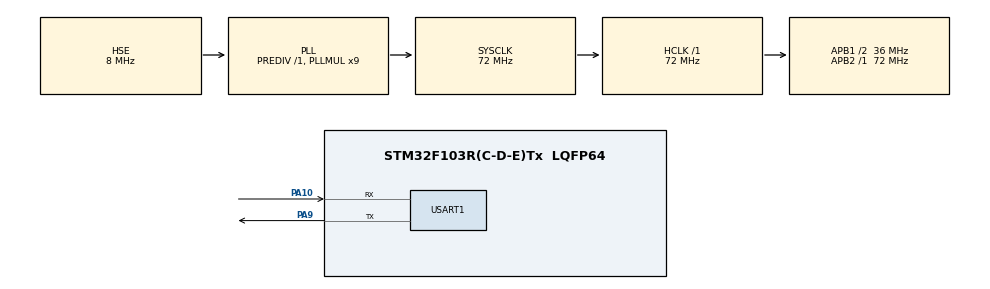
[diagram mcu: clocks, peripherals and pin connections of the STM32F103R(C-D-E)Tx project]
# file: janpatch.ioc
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Mcu.Family=STM32F1
Mcu.Name=STM32F103R(C-D-E)Tx
Mcu.Package=LQFP64
NVIC.PriorityGroup=NVIC_PRIORITYGROUP_4
PA10.Mode=Asynchronous
PA10.Signal=USART1_RX
PA13.Mode=Serial_Wire
PA13.Signal=SYS_JTMS-SWDIO
PA14.Mode=Serial_Wire
PA14.Signal=SYS_JTCK-SWCLK
PA9.Mode=Asynchronous
PA9.Signal=USART1_TX
PC14-OSC32_IN.Mode=LSE-External-Oscillator
PC14-OSC32_IN.Signal=RCC_OSC32_IN
PC15-OSC32_OUT.Mode=LSE-External-Oscillator
PC15-OSC32_OUT.Signal=RCC_OSC32_OUT
PD0-OSC_IN.Mode=HSE-External-Oscillator
PD0-OSC_IN.Signal=RCC_OSC_IN
PD1-OSC_OUT.Mode=HSE-External-Oscillator
PD1-OSC_OUT.Signal=RCC_OSC_OUT
ProjectManager.HeapSize=0x200
ProjectManager.StackSize=0x400
ProjectManager.TargetToolchain=MDK-ARM V5.32
RCC.AHBFreq_Value=72000000
RCC.APB1CLKDivider=RCC_HCLK_DIV2
RCC.APB1Freq_Value=36000000
RCC.APB1TimFreq_Value=72000000
RCC.APB2Freq_Value=72000000
RCC.APB2TimFreq_Value=72000000
RCC.HCLKFreq_Value=72000000
RCC.PLLMUL=RCC_PLL_MUL9
RCC.PLLSourceVirtual=RCC_PLLSOURCE_HSE
RCC.SYSCLKFreq_VALUE=72000000
RCC.SYSCLKSource=RCC_SYSCLKSOURCE_PLLCLK
RCC.USBFreq_Value=72000000
USART1.VirtualMode=VM_ASYNC
board=custom

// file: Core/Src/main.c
/* USER CODE BEGIN Header */
/**
  ******************************************************************************
  * @file           : main.c
  * @brief          : Main program body
  ******************************************************************************
  * @attention
  *
  * Copyright (c) 2024 STMicroelectronics.
  * All rights reserved.
  *
  * This software is licensed under terms that can be found in the LICENSE file
  * in the root directory of this software component.
  * If no LICENSE file comes with this software, it is provided AS-IS.
  *
  ******************************************************************************
  */
/* USER CODE END Header */
#include "main.h"
#include "usart.h"
#include "gpio.h"

/* USER CODE BEGIN Includes */
#include "stdio.h"
#define FOTA_TARGET_ADDRESS 0x08010000
uint32_t Flash_Read(uint32_t address, uint8_t *data, uint32_t length)
{
    while(length--)
    {
        *(data++)=*((uint8_t*)address++);
    }
		return 0;
}

uint32_t Flash_Erase(uint32_t address)
{
    FLASH_EraseInitTypeDef FlashSet;
    FlashSet.TypeErase = FLASH_TYPEERASE_PAGES;
    FlashSet.PageAddress = address;
    FlashSet.NbPages = 1;
    /*设置PageError，调用擦除函数*/
    uint32_t PageError = 0;
    HAL_FLASH_Unlock();
    HAL_FLASHEx_Erase(&FlashSet, &PageError);
    HAL_FLASH_Lock();
		return 0;
}

uint32_t Flash_Write(uint32_t address, uint8_t *data, uint32_t length)
{
    uint8_t buff[4] = {0xFF, 0xFF, 0xFF, 0xFF};
    uint32_t len = length / 4;
    // 解锁Flash
    HAL_FLASH_Unlock();

    // 写入数据到指定地址
    while(len--)
    {
      HAL_FLASH_Program(FLASH_TYPEPROGRAM_WORD, address, *((uint32_t *)data));
      address += 4;
      data += 4;
    }

    len = length % 4;

    for(int i = 0; i < len; i++)
      buff[i] = data[i];

    HAL_FLASH_Program(FLASH_TYPEPROGRAM_WORD, address, *((uint32_t *)buff));

    // 重新锁定Flash
    HAL_FLASH_Lock();
		return 0;
}

/* USER CODE END Includes */

/* USER CODE BEGIN PTD */
#include "janpatch.h"

static janpatch_file_t source = {
  .file_address = FOTA_TARGET_ADDRESS,
  // .file_size = 47352,
};

static janpatch_file_t patch = {
  .file_address = 0x08030000,
  // .file_size = 8580,
};

static janpatch_file_t target = {
  .file_address = FOTA_TARGET_ADDRESS,
  .file_size = 64 * 1024,
};

static struct janpatch_mcu_config janpatch_mcu_config = {
  .flash_erase = Flash_Erase,
  .flash_read = Flash_Read,
  .flash_write = Flash_Write,
};

/* USER CODE END PTD */

void SystemClock_Config(void);

int main(void)
{

  /* MCU Configuration--------------------------------------------------------*/

  /* Reset of all peripherals, Initializes the Flash interface and the Systick. */
  HAL_Init();

  /* Configure the system clock */
  SystemClock_Config();

  /* Initialize all configured peripherals */
  MX_GPIO_Init();
  MX_USART1_UART_Init();
  /* USER CODE BEGIN 2 */
  uint8_t ret = 0;
  ret = janpatch_mcu_cinfig_fota(&janpatch_mcu_config, &source, &patch, &target);
  // if(ret == 0){
  //   uint8_t val = 0;
  //   for(int i = 0; i < target.file_seek; i++) {
  //     Flash_Read(FOTA_TARGET_ADDRESS + i, &val, 1);
  //       if(i % 2048 == 0) printf("\r\n");
  //     if(i % 16 == 0) printf("\r\n%08X: ", i);
  //     printf("%02X ", val);
  //   }
  // }
  /* Infinite loop */
  while (1)
  {

  }
}

void SystemClock_Config(void)
{
  RCC_OscInitTypeDef RCC_OscInitStruct = {0};
  RCC_ClkInitTypeDef RCC_ClkInitStruct = {0};

  /** Initializes the RCC Oscillators according to the specified parameters
  * in the RCC_OscInitTypeDef structure.
  */
  RCC_OscInitStruct.OscillatorType = RCC_OSCILLATORTYPE_HSE;
  RCC_OscInitStruct.HSEState = RCC_HSE_ON;
  RCC_OscInitStruct.HSEPredivValue = RCC_HSE_PREDIV_DIV1;
  RCC_OscInitStruct.HSIState = RCC_HSI_ON;
  RCC_OscInitStruct.PLL.PLLState = RCC_PLL_ON;
  RCC_OscInitStruct.PLL.PLLSource = RCC_PLLSOURCE_HSE;
  RCC_OscInitStruct.PLL.PLLMUL = RCC_PLL_MUL9;
  if (HAL_RCC_OscConfig(&RCC_OscInitStruct) != HAL_OK)
  {
    Error_Handler();
  }

  /** Initializes the CPU, AHB and APB buses clocks
  */
  RCC_ClkInitStruct.ClockType = RCC_CLOCKTYPE_HCLK|RCC_CLOCKTYPE_SYSCLK
                              |RCC_CLOCKTYPE_PCLK1|RCC_CLOCKTYPE_PCLK2;
  RCC_ClkInitStruct.SYSCLKSource = RCC_SYSCLKSOURCE_PLLCLK;
  RCC_ClkInitStruct.AHBCLKDivider = RCC_SYSCLK_DIV1;
  RCC_ClkInitStruct.APB1CLKDivider = RCC_HCLK_DIV2;
  RCC_ClkInitStruct.APB2CLKDivider = RCC_HCLK_DIV1;

  if (HAL_RCC_ClockConfig(&RCC_ClkInitStruct, FLASH_LATENCY_2) != HAL_OK)
  {
    Error_Handler();
  }
}

void Error_Handler(void)
{
  __disable_irq();
  while (1)
  {
  }
}
